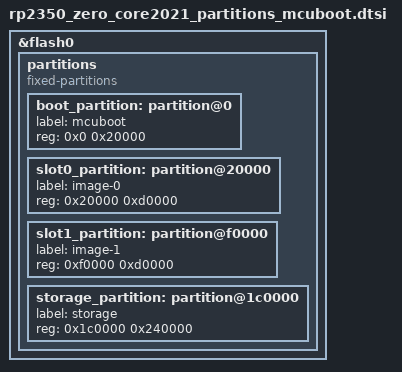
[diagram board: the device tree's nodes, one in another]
/*
 * Copyright (c) 2026 zlrs contributors
 *
 * SPDX-License-Identifier: Apache-2.0
 *
 * Partition table with MCUboot (4 MB). The layout matches the Zephyr tree's raspberrypi/
 * partitions_4M_sysbuild.dtsi except that the bootloader grows from 64 KB to 128 KB: the
 * measured MCUboot with serial recovery (mcumgr over UART) already takes 61.6 KB, 96% of 64 KB,
 * leaving no room for more code; 128 KB leaves headroom for USB CDC recovery and the like.
 *
 *   0x000000  mcuboot   128 KB   RP2350 bootrom starts here
 *   0x020000  slot0     832 KB   application (signed), zephyr,code-partition
 *   0x0F0000  slot1     832 KB   upgrade images land here, MCUboot swaps
 *   0x1C0000  storage  2.25 MB   NVS: root key, device id, pairing record, failsafe values
 */

&flash0 {
	status = "okay";

	partitions {
		compatible = "fixed-partitions";
		#address-cells = <1>;
		#size-cells = <1>;

		boot_partition: partition@0 {
			label = "mcuboot";
			reg = <0x0 0x20000>;
		};

		slot0_partition: partition@20000 {
			label = "image-0";
			reg = <0x20000 0xd0000>;
		};

		slot1_partition: partition@f0000 {
			label = "image-1";
			reg = <0xf0000 0xd0000>;
		};

		storage_partition: partition@1c0000 {
			label = "storage";
			reg = <0x1c0000 0x240000>;
		};
	};
};
